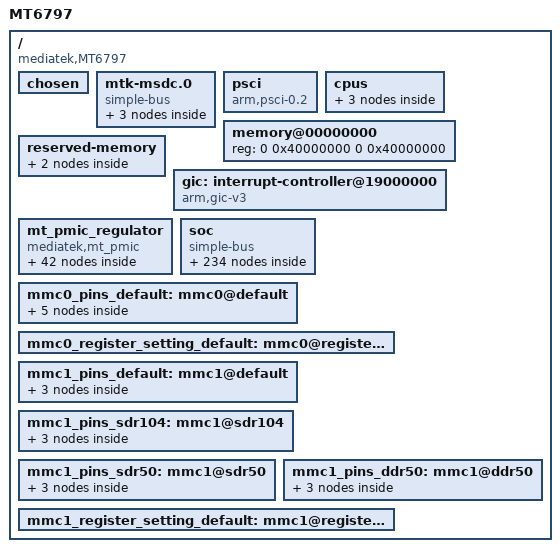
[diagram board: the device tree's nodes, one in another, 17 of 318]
/*
 * Mediatek's MT6797 SoC device tree source
 *
 * Copyright (c) 2013 MediaTek Co., Ltd.
 *              http://www.mediatek.com
 *
 */

#include <dt-bindings/interrupt-controller/arm-gic.h>
#include <dt-bindings/interrupt-controller/irq.h>
#include <dt-bindings/mmc/mt67xx-msdc.h>

/{
	model = "MT6797";
	compatible = "mediatek,MT6797";
	interrupt-parent = <&gic>;
	#address-cells = <2>;
	#size-cells = <2>;

	/* chosen */
	chosen {
		bootargs = "console=tty0 console=ttyMT0,921600n1 root=/dev/ram \
initrd=0x44000000,0x200000 loglevel=8 androidboot.selinux=permissive";
	};

	/* Do not put any bus before mtk-msdc, because it should be mtk-msdc.0 for partition device node usage */
	/* Kernel-3.18 can't transfer this node to mtk-msdc.0. So workaround here */
	mtk-msdc.0 {
		compatible = "simple-bus";
		#address-cells = <1>;
		#size-cells = <1>;
		ranges = <0 0 0 0xffffffff>;
		MSDC0@0x11230000 {
			compatible = "mediatek,MSDC0";
			reg = <0x11230000 0x10000>;
			interrupts = <GIC_SPI 79 IRQ_TYPE_LEVEL_LOW>;
			clk_src = /bits/ 8 <MSDC50_CLKSRC_400MHZ>;
			bus-width = <8>;
			max-frequency = <200000000>;
			cap-mmc-highspeed;
			msdc-sys-suspend;
			/* mmc-ddr-1_8v; */
			/* mmc-hs200-1_8v; */
			/* mmc-hs400-1_8v; */
			non-removable;
			pinctl = <&mmc0_pins_default>;
			register_setting = <&mmc0_register_setting_default>;
			host_function = /bits/ 8 <MSDC_EMMC>;
			bootable;
		};

		MSDC1@0x11240000 {
			compatible = "mediatek,MSDC1";
			reg = <0x11240000 0x10000>;
			interrupts = <GIC_SPI 80 IRQ_TYPE_LEVEL_LOW>;
			clk_src = /bits/ 8 <MSDC30_CLKSRC_200MHZ>;
			bus-width = <4>;
			max-frequency = <200000000>;
			msdc-sys-suspend;
			cap-sd-highspeed;
			sd-uhs-sdr12;
			sd-uhs-sdr25;
			sd-uhs-sdr50;
			sd-uhs-sdr104;
			sd-uhs-ddr50;
			pinctl = <&mmc1_pins_default>;
			pinctl_sdr104 = <&mmc1_pins_sdr104>;
			pinctl_sdr50 = <&mmc1_pins_sdr50>;
			pinctl_ddr50 = <&mmc1_pins_ddr50>;
			register_setting = <&mmc1_register_setting_default>;
			host_function = /bits/ 8 <MSDC_SD>;
			cd_level = /bits/ 8 <MSDC_CD_LOW>;
		};

		MSDC2@0x11250000 {
			compatible = "mediatek,MSDC2";
			reg = <0x11250000 0x10000>;
			interrupts = <GIC_SPI 81 IRQ_TYPE_LEVEL_LOW>;
		};

	};

	psci {
		compatible	= "arm,psci-0.2";
		method		= "smc";
		cpu_suspend	= <0x84000001>;
		cpu_off		= <0x84000002>;
		cpu_on		= <0x84000003>;
		affinity_info	= <0x84000004>;
	};

	cpus {
		#address-cells = <1>;
		#size-cells = <0>;

		cpu0: cpu@0 {
			device_type = "cpu";
			compatible = "arm,cortex-a53";
			reg = <0x000>;
			enable-method = "psci";
			cpu-release-addr = <0x0 0x40000200>;
			clock-frequency = <2000000000>;
		};

		cpu4: cpu@4 {
			device_type = "cpu";
			compatible = "arm,cortex-a53";
			reg = <0x100>;
			enable-method = "psci";
			cpu-release-addr = <0x0 0x40000200>;
			clock-frequency = <2000000000>;
		};

		cpu8: cpu@8 {
			device_type = "cpu";
			compatible = "arm,armv8";
			reg = <0x200>;
			enable-method = "psci";
			cpu-release-addr = <0x0 0x40000200>;
			clock-frequency = <2000000000>;
		};

	};

	memory@00000000 {
		device_type = "memory";
		reg = <0 0x40000000 0 0x40000000>;
		/*TODO: add memory node here*/
	};
	reserved-memory {
		#address-cells = <2>;
		#size-cells = <2>;
		ranges;

		ram_console-reserved-memory {
			compatible = "ram_console-reserve-memory";
			reg = <0 0x43F00000 0 0x10000>;
		};

		minirdump-reserved-memory {
			compatible = "minirdump-reserve-memory";
			reg = <0 0x43FF0000 0 0x10000>;
		};
	};
	gic: interrupt-controller@19000000 {
		compatible = "arm,gic-v3";
		#interrupt-cells = <3>;
		#address-cells = <2>;
		#size-cells = <2>;
		#redistributor-regions = <1>;
		interrupt-controller;
		reg = <0 0x19000000 0 0x40000>, // distributor
			<0 0x19200000 0 0x200000>, // redistributor
			<0 0x10220620 0 0x001000>; // INTPOL
		interrupts = <GIC_PPI 9 IRQ_TYPE_LEVEL_HIGH>;

	};
	mt_pmic_regulator {
		compatible = "mediatek,mt_pmic";
		/*reg = <0x01>*/
		buck_regulators {
			compatible = "mediatek,mt_pmic_buck_regulators";
			mt_pmic_vcore_buck_reg: buck_vcore {
				regulator-name = "vcore";
				regulator-min-microvolt = <600000>;
				regulator-max-microvolt = <1393750>;
				regulator-ramp-delay = <6250>;
				regulator-enable-ramp-delay = <180>;
			};
			mt_pmic_vgpu_buck_reg: buck_vgpu {
				regulator-name = "vgpu";
				regulator-min-microvolt = <600000>;
				regulator-max-microvolt = <1393750>;
				regulator-ramp-delay = <6250>;
				regulator-enable-ramp-delay = <180>;
				regulator-always-on;
				regulator-boot-on;
			};
			mt_pmic_vmodem_buck_reg: buck_vmodem {
				regulator-name = "vmodem";
				regulator-min-microvolt = <600000>;
				regulator-max-microvolt = <1393750>;
				regulator-ramp-delay = <6250>;
				regulator-enable-ramp-delay = <180>;
				regulator-always-on;
				regulator-boot-on;
			};
			mt_pmic_vmd1_buck_reg: buck_vmd1 {
				regulator-name = "vmd1";
				regulator-min-microvolt = <600000>;
				regulator-max-microvolt = <1393750>;
				regulator-ramp-delay = <6250>;
				regulator-enable-ramp-delay = <180>;
				regulator-always-on;
				regulator-boot-on;
			};
			mt_pmic_vsram_md_buck_reg: buck_vsram_md {
				regulator-name = "vsram_md";
				regulator-min-microvolt = <600000>;
				regulator-max-microvolt = <1393750>;
				regulator-ramp-delay = <6250>;
				regulator-enable-ramp-delay = <180>;
				regulator-always-on;
				regulator-boot-on;
			};
			mt_pmic_vs1_buck_reg: buck_vs1 {
				regulator-name = "vs1";
				regulator-min-microvolt = <600000>;
				regulator-max-microvolt = <1393750>;
				regulator-ramp-delay = <6250>;
				regulator-enable-ramp-delay = <180>;
				regulator-always-on;
				regulator-boot-on;
			};
			mt_pmic_vs2_buck_reg: buck_vs2 {
				regulator-name = "vs2";
				regulator-min-microvolt = <600000>;
				regulator-max-microvolt = <1393750>;
				regulator-ramp-delay = <6250>;
				regulator-enable-ramp-delay = <180>;
				regulator-always-on;
				regulator-boot-on;
			};
			mt_pmic_vpa_buck_reg: buck_vpa {
				regulator-name = "vpa";
				regulator-min-microvolt = <600000>;
				regulator-max-microvolt = <1393750>;
				regulator-ramp-delay = <6250>;
				regulator-enable-ramp-delay = <180>;
				regulator-always-on;
				regulator-boot-on;
			};
			mt_pmic_vsram_proc_buck_reg: buck_vsram_proc {
				regulator-name = "vsram_proc";
				regulator-min-microvolt = <600000>;
				regulator-max-microvolt = <1393750>;
				regulator-ramp-delay = <6250>;
				regulator-enable-ramp-delay = <180>;
				regulator-always-on;
				regulator-boot-on;
			};
		};	/* End of buck_regulators */
		ldo_regulators {
			compatible = "mediatek,mt_pmic_ldo_regulators";
			mt_pmic_va18_ldo_reg: ldo_va18 {
				regulator-name = "va18";
				regulator-min-microvolt = <1800000>;
				regulator-max-microvolt = <1800000>;
				regulator-enable-ramp-delay = <264>;
				regulator-boot-on;
			};
			mt_pmic_vtcxo24_ldo_reg: ldo_vtcxo24 {
				regulator-name = "vtcxo24";
				regulator-min-microvolt = <1800000>;
				regulator-max-microvolt = <2800000>;
				regulator-enable-ramp-delay = <110>;
				regulator-boot-on;
			};
			mt_pmic_vtcxo28_ldo_reg: ldo_vtcxo28 {
				regulator-name = "vtcxo28";
				regulator-min-microvolt = <1800000>;
				regulator-max-microvolt = <2800000>;
				regulator-enable-ramp-delay = <110>;
			};
			mt_pmic_vcn28_ldo_reg: ldo_vcn28 {
				regulator-name = "vcn28";
				regulator-min-microvolt = <1800000>;
				regulator-max-microvolt = <2800000>;
				regulator-enable-ramp-delay = <264>;
			};
			mt_pmic_vcama_ldo_reg: ldo_vcama {
				regulator-name = "vcama";
				regulator-min-microvolt = <1500000>;
				regulator-max-microvolt = <2800000>;
				regulator-enable-ramp-delay = <264>;
			};
			mt_pmic_vusb33_ldo_reg: ldo_vusb33 {
				regulator-name = "vusb33";
				regulator-min-microvolt = <3300000>;
				regulator-max-microvolt = <3300000>;
				regulator-enable-ramp-delay = <264>;
				regulator-boot-on;
			};
			mt_pmic_vsim1_ldo_reg: ldo_vsim1 {
				regulator-name = "vsim1";
				regulator-min-microvolt = <1700000>;
				regulator-max-microvolt = <3100000>;
				regulator-enable-ramp-delay = <264>;
			};
			mt_pmic_vsim2_ldo_reg: ldo_vsim2 {
				regulator-name = "vsim2";
				regulator-min-microvolt = <1700000>;
				regulator-max-microvolt = <3100000>;
				regulator-enable-ramp-delay = <264>;
			};
			mt_pmic_vemc_ldo_reg: ldo_vemc {
				regulator-name = "vemc_3v3";
				regulator-min-microvolt = <3000000>;
				regulator-max-microvolt = <3300000>;
				regulator-enable-ramp-delay = <44>;
				regulator-boot-on;
			};
			mt_pmic_vmch_ldo_reg: ldo_vmch {
				regulator-name = "vmch";
				regulator-min-microvolt = <3000000>;
				regulator-max-microvolt = <3300000>;
				regulator-enable-ramp-delay = <44>;
				regulator-boot-on;
			};
			mt_pmic_vio28_ldo_reg: ldo_vio28 {
				regulator-name = "vio28";
				regulator-min-microvolt = <2800000>;
				regulator-max-microvolt = <2800000>;
				regulator-enable-ramp-delay = <264>;
				regulator-boot-on;
			};
			mt_pmic_vibr_ldo_reg: ldo_vibr {
				regulator-name = "vibr";
				regulator-min-microvolt = <1200000>;
				regulator-max-microvolt = <3300000>;
				regulator-enable-ramp-delay = <44>;
			};
			mt_pmic_vcamd_ldo_reg: ldo_vcamd {
				regulator-name = "vcamd";
				regulator-min-microvolt = <900000>;
				regulator-max-microvolt = <1210000>;
				regulator-enable-ramp-delay = <264>;
			};
			mt_pmic_vrf18_ldo_reg: ldo_vrf18 {
				regulator-name = "vrf18";
				regulator-min-microvolt = <1000000>;
				regulator-max-microvolt = <1810000>;
				regulator-enable-ramp-delay = <220>;
			};
			mt_pmic_vio18_ldo_reg: ldo_vio18 {
				regulator-name = "vio18";
				regulator-min-microvolt = <1800000>;
				regulator-max-microvolt = <1800000>;
				regulator-enable-ramp-delay = <264>;
				regulator-boot-on;
			};
			mt_pmic_vcn18_ldo_reg: ldo_vcn18 {
				regulator-name = "vcn18";
				regulator-min-microvolt = <1800000>;
				regulator-max-microvolt = <1800000>;
				regulator-enable-ramp-delay = <44>;
			};
			mt_pmic_vcamio_ldo_reg: ldo_vcamio {
				regulator-name = "vcamio";
				regulator-min-microvolt = <1200000>;
				regulator-max-microvolt = <1800000>;
				regulator-enable-ramp-delay = <220>;
			};
			mt_pmic_vsram_proc_ldo_reg: ldo_vsram_proc {
				regulator-name = "vsram_proc";
				regulator-min-microvolt = <600000>;
				regulator-max-microvolt = <1393750>;
				regulator-enable-ramp-delay = <220>;
				regulator-boot-on;
			};
			mt_pmic_vxo22_ldo_reg: ldo_vxo22 {
				regulator-name = "vxo22";
				regulator-min-microvolt = <1800000>;
				regulator-max-microvolt = <2800000>;
				regulator-enable-ramp-delay = <110>;
				regulator-boot-on;
			};
			mt_pmic_vrf12_ldo_reg: ldo_vrf12 {
				regulator-name = "vrf12";
				regulator-min-microvolt = <900000>;
				regulator-max-microvolt = <1200000>;
				regulator-enable-ramp-delay = <220>;
			};
			mt_pmic_va10_ldo_reg: ldo_va10 {
				regulator-name = "va10";
				regulator-min-microvolt = <900000>;
				regulator-max-microvolt = <1800000>;
				regulator-enable-ramp-delay = <264>;
				regulator-boot-on;
			};
			mt_pmic_vdram_ldo_reg: ldo_vdram {
				regulator-name = "vdram";
				regulator-min-microvolt = <900000>;
				regulator-max-microvolt = <1210000>;
				regulator-enable-ramp-delay = <264>;
				regulator-boot-on;
			};
			mt_pmic_vmipi_ldo_reg: ldo_vmipi {
				regulator-name = "vmipi";
				regulator-min-microvolt = <900000>;
				regulator-max-microvolt = <1800000>;
				regulator-enable-ramp-delay = <264>;
			};
			mt_pmic_vgp3_ldo_reg: ldo_vgp3 {
				regulator-name = "vgp3";
				regulator-min-microvolt = <1000000>;
				regulator-max-microvolt = <1810000>;
				regulator-enable-ramp-delay = <264>;
			};
			mt_pmic_vbif28_ldo_reg: ldo_vbif28 {
				regulator-name = "vbif28";
				regulator-min-microvolt = <2800000>;
				regulator-max-microvolt = <2800000>;
				regulator-enable-ramp-delay = <264>;
			};
			mt_pmic_vefuse_ldo_reg: ldo_vefuse {
				regulator-name = "vefuse";
				regulator-min-microvolt = <1200000>;
				regulator-max-microvolt = <2200000>;
				regulator-enable-ramp-delay = <264>;
			};
			mt_pmic_vcn33_bt_ldo_reg: ldo_vcn33_bt {
				regulator-name = "vcn33_bt";
				regulator-min-microvolt = <3300000>;
				regulator-max-microvolt = <3600000>;
				regulator-enable-ramp-delay = <264>;
			};
			mt_pmic_vcn33_wifi_ldo_reg: ldo_vcn33_wifi {
				regulator-name = "vcn33_wifi";
				regulator-min-microvolt = <3300000>;
				regulator-max-microvolt = <3600000>;
				regulator-enable-ramp-delay = <264>;
			};
			mt_pmic_vldo28_ldo_reg: ldo_vldo28 {
				regulator-name = "vldo28";
				regulator-min-microvolt = <2800000>;
				regulator-max-microvolt = <2800000>;
				regulator-enable-ramp-delay = <264>;
			};
			mt_pmic_vmc_ldo_reg: ldo_vmc {
				regulator-name = "vmc";
				regulator-min-microvolt = <1200000>;
				regulator-max-microvolt = <3300000>;
				regulator-enable-ramp-delay = <44>;
				regulator-boot-on;
			};
		};/* End of ldo_regulators */
		regulators_supply {
			compatible = "mediatek,mt_pmic_regulator_supply";
			va18-supply = <&mt_pmic_va18_ldo_reg>;
			vtcxo24-supply = <&mt_pmic_vtcxo24_ldo_reg>;
			vtcxo28-supply = <&mt_pmic_vtcxo28_ldo_reg>;
			vsim1-supply = <&mt_pmic_vsim1_ldo_reg>;
			vsim2-supply = <&mt_pmic_vsim2_ldo_reg>;
			vemc-supply = <&mt_pmic_vemc_ldo_reg>;
			vmch-supply = <&mt_pmic_vmch_ldo_reg>;
			vmc-supply = <&mt_pmic_vmc_ldo_reg>;
			vio28-supply = <&mt_pmic_vio28_ldo_reg>;
			vibr-supply = <&mt_pmic_vibr_ldo_reg>;
			vrf18-supply = <&mt_pmic_vrf18_ldo_reg>;
			vio18-supply = <&mt_pmic_vio18_ldo_reg>;
			vsram_proc-supply = <&mt_pmic_vsram_proc_ldo_reg>;
			vxo22-supply = <&mt_pmic_vxo22_ldo_reg>;
			vrf12-supply = <&mt_pmic_vrf12_ldo_reg>;
			vdram-supply = <&mt_pmic_vdram_ldo_reg>;
			vmipi-supply = <&mt_pmic_vmipi_ldo_reg>;
			vbif28-supply = <&mt_pmic_vbif28_ldo_reg>;
			vefuse-supply = <&mt_pmic_vefuse_ldo_reg>;
			vcn18-supply = <&mt_pmic_vcn18_ldo_reg>;
			vcn28-supply = <&mt_pmic_vcn28_ldo_reg>;
			vcn33_bt-supply = <&mt_pmic_vcn33_bt_ldo_reg>;
			vcn33_wifi-supply = <&mt_pmic_vcn33_wifi_ldo_reg>;
		};/* End of regulators_supply */
	};/* End of mt_pmic_regulator */
	soc {
		compatible = "simple-bus";
		#address-cells = <1>;
		#size-cells = <1>;
		ranges = <0 0 0 0xffffffff>;

		chipid@08000000 {
			compatible = "mediatek,chipid";
			reg = <0x08000000 0x0004>,
					<0x08000004 0x0004>,
					<0x08000008 0x0004>,
					<0x0800000C 0x0004>;
		};

		topckgen@10000000 {
			compatible = "mediatek,topckgen";
			reg = <0x10000000 0x1000>;
		};

		infracfg_ao@10001000 {
			compatible = "mediatek,infracfg_ao";
			reg = <0x10001000 0x1000>;
		};

		iocfg_l@10002000 {
			compatible = "mediatek,iocfg_l";
			reg = <0x10002000 0x400>;
		};

		iocfg_b@10002400 {
			compatible = "mediatek,iocfg_b";
			reg = <0x10002400 0x400>;
		};

		iocfg_r@10002800 {
			compatible = "mediatek,iocfg_r";
			reg = <0x10002800 0x400>;
		};

		iocfg_t@10002c00 {
			compatible = "mediatek,iocfg_t";
			reg = <0x10002c00 0x400>;
		};

		pericfg@10003000 {
			compatible = "mediatek,pericfg";
			reg = <0x10003000 0x1000>;
		};

		dramc_conf@10004000 {
			compatible = "mediatek,dramc_conf";
			reg = <0x10004000 0x1000>;
		};

		gpio@10005000 {
			compatible = "mediatek,gpio";
			reg = <0x10005000 0x1000>;
		};

		sleep@10006000 {
			compatible = "mediatek,sleep";
			reg = <0x10006000 0x1000>;
			interrupts = <GIC_SPI 180 IRQ_TYPE_LEVEL_LOW>;
		};

		toprgu: toprgu@10007000 {
			compatible = "mediatek,mt6797-toprgu";
			reg = <0x10007000 0x1000>;
			interrupts = <GIC_SPI 137 IRQ_TYPE_EDGE_FALLING>;
		};

		cpuxgpt: cpuxgpt@10220000 {
			compatible = "mediatek,mt6797-cpuxgpt";
			reg = <0x10220000 0x1000>;
			interrupts = <GIC_SPI 64 IRQ_TYPE_LEVEL_HIGH>,
				<GIC_SPI 65 IRQ_TYPE_LEVEL_HIGH>,
				<GIC_SPI 66 IRQ_TYPE_LEVEL_HIGH>,
				<GIC_SPI 67 IRQ_TYPE_LEVEL_HIGH>,
				<GIC_SPI 68 IRQ_TYPE_LEVEL_HIGH>,
				<GIC_SPI 69 IRQ_TYPE_LEVEL_HIGH>,
				<GIC_SPI 70 IRQ_TYPE_LEVEL_HIGH>,
				<GIC_SPI 71 IRQ_TYPE_LEVEL_HIGH>,
				<GIC_SPI 322 IRQ_TYPE_LEVEL_HIGH>,
				<GIC_SPI 323 IRQ_TYPE_LEVEL_HIGH>;
		};

		apxgpt: apxgpt@10008000 {
			compatible = "mediatek,mt6797-apxgpt";
			reg = <0x10008000 0x1000>;
			interrupts = <GIC_SPI 169 IRQ_TYPE_LEVEL_LOW>;
			clock-frequency = <13000000>;
		};

		timer {
			compatible = "arm,armv8-timer";
			interrupts = <GIC_PPI 13 IRQ_TYPE_LEVEL_LOW>, /*Secure Physical Timer Event*/
				<GIC_PPI 14 IRQ_TYPE_LEVEL_LOW>, /*Non-Secure Physical Timer Event*/
				<GIC_PPI 11 IRQ_TYPE_LEVEL_LOW>, /*Virtual Timer Event*/
				<GIC_PPI 10 IRQ_TYPE_LEVEL_LOW>; /*Hypervisor Timer Event*/
				clock-frequency = <13000000>;
		};

		rsvd@10009000 {
			compatible = "mediatek,rsvd";
			reg = <0x10009000 0x1000>;
		};

		sej@1000a000 {
			compatible = "mediatek,sej";
			reg = <0x1000a000 0x1000>;
			interrupts = <GIC_SPI 196 IRQ_TYPE_LEVEL_LOW>;
		};

		eintc: eintc@1000b000 {
			compatible = "mediatek,mt-eic";
			reg = <0x1000b000 0x1000>;
			interrupts = <GIC_SPI 170 IRQ_TYPE_LEVEL_HIGH>;

			#interrupt-cells = <2>;
			interrupt-controller;

			max_eint_num = <192>;
			mapping_table_entry = <0>;
		};

		apmixed@1000c000 {
			compatible = "mediatek,apmixed";
			reg = <0x1000c000 0x1000>;
		};

		fhctl@1000cf00 {
			compatible = "mediatek,fhctl";
			reg = <0x1000cf00 0x100>;
		};

		pwrap@1000d000 {
			compatible = "mediatek,pwrap";
			reg = <0x1000d000 0x1000>;
			interrupts = <GIC_SPI 178 IRQ_TYPE_LEVEL_HIGH>;
		};

		devapc_ao@1000e000 {
			compatible = "mediatek,devapc_ao";
			reg = <0x1000e000 0x1000>;
		};

		ddrphy@1000f000 {
			compatible = "mediatek,ddrphy";
			reg = <0x1000f000 0x1000>;
		};

		kp@10010000 {
			compatible = "mediatek,kp";
			reg = <0x10010000 0x1000>;
			interrupts = <GIC_SPI 179 IRQ_TYPE_EDGE_FALLING>;
		};

		topmisc@10011000 {
			compatible = "mediatek,topmisc";
			reg = <0x10011000 0x1000>;
		};

		ddrphy_b@10012000 {
			compatible = "mediatek,ddrphy_b";
			reg = <0x10012000 0x1000>;
		};

		dramc_conf_b@10013000 {
			compatible = "mediatek,dramc_conf_b";
			reg = <0x10013000 0x1000>;
		};

		cldma_ao_ap@10014000 {
			compatible = "mediatek,cldma_ao_ap";
			reg = <0x10014000 0x1000>;
		};

		cldma_ao_md@10015000 {
			compatible = "mediatek,cldma_ao_md";
			reg = <0x10015000 0x1000>;
		};

		aes_top0@10016000 {
			compatible = "mediatek,aes_top0";
			reg = <0x10016000 0x1000>;
		};

		aes_top1@10017000 {
			compatible = "mediatek,aes_top1";
			reg = <0x10017000 0x1000>;
		};

		ddrphy_c@10018000 {
			compatible = "mediatek,ddrphy_c";
			reg = <0x10018000 0x1000>;
		};

		ddrphy_d@10019000 {
			compatible = "mediatek,ddrphy_d";
			reg = <0x10019000 0x1000>;
		};

		mcumixed@1001a000 {
			compatible = "mediatek,mcumixed";
			reg = <0x1001a000 0x1000>;
		};

		c2kmisc@1001b000 {
			compatible = "mediatek,c2kmisc";
			reg = <0x1001b000 0x1000>;
		};

		modem_temp@1001c000 {
			compatible = "mediatek,modem_temp";
			reg = <0x1001c000 0x1000>;
		};


		scp: scp@10020000 {
			compatible = "mediatek,scp";
			status = "disabled";
			reg = <0 0x10020000 0 0x80000>, // sram
			<0 0x100a0000 0 0x1000>,  // cfgreg
			<0 0x100a4000 0 0x1000>;	// clkctrl
			interrupts = <GIC_SPI 199 IRQ_TYPE_LEVEL_HIGH>;
		};

		emi_mpu@10200000 {
			compatible = "mediatek,emi_mpu";
			reg = <0x10200000 0x1000>;
		};

		infracfg@10201000 {
			compatible = "mediatek,infracfg";
			reg = <0x10201000 0x1000>;
		};

		sramrom@10202000 {
			compatible = "mediatek,sramrom";
			reg = <0x10202000 0x1000>;
		};

		emi@10203000 {
			compatible = "mediatek,emi";
			reg = <0x10203000 0x1000>;
			interrupts = <GIC_SPI 143 IRQ_TYPE_LEVEL_LOW>;
		};

		sys_cirq@10204000 {
			compatible = "mediatek,sys_cirq";
			reg = <0x10204000 0x1000>;
			interrupts = <GIC_SPI 291 IRQ_TYPE_EDGE_FALLING>;
		};

		m4u@10205000 {
			cell-index = <0>;
			compatible = "mediatek,m4u";
			reg = <0x10205000 0x1000>;
			interrupts = <GIC_SPI 156 IRQ_TYPE_LEVEL_LOW>;
		};

		efusec@10206000 {
			compatible = "mediatek,efusec";
			reg = <0x10206000 0x1000>;
		};

		devapc@10207000 {
			compatible = "mediatek,devapc";
			reg = <0x10207000 0x1000>;
			interrupts = <GIC_SPI 141 IRQ_TYPE_LEVEL_LOW>;
		};

		bus_dbg@10208000 {
			compatible = "mediatek,bus_dbg";
			reg = <0x10208000 0x1000>;
			interrupts = <GIC_SPI 140 IRQ_TYPE_LEVEL_LOW>;
		};

		ap_ccif0@10209000 {
			compatible = "mediatek,ap_ccif0";
			reg = <0x10209000 0x1000>;
			interrupts = <GIC_SPI 147 IRQ_TYPE_LEVEL_LOW>;
		};

		md_ccif0@1020a000 {
			compatible = "mediatek,md_ccif0";
			reg = <0x1020a000 0x1000>;
		};

		ap_ccif1@1020b000 {
			compatible = "mediatek,ap_ccif1";
			reg = <0x1020b000 0x1000>;
			interrupts = <GIC_SPI 149 IRQ_TYPE_LEVEL_LOW>;
		};

		ap_ccif1@1020c000 {
			compatible = "mediatek,ap_ccif1";
			reg = <0x1020c000 0x1000>;
		};

		infra_mbist@1020d000 {
			compatible = "mediatek,infra_mbist";
			reg = <0x1020d000 0x1000>;
		};

		dramc_nao@1020e000 {
			compatible = "mediatek,dramc_nao";
			reg = <0x1020e000 0x1000>;
			interrupts = <GIC_SPI 158 IRQ_TYPE_EDGE_FALLING>;
		};

		trng@1020f000 {
			compatible = "mediatek,trng";
			reg = <0x1020f000 0x1000>;
			interrupts = <GIC_SPI 148 IRQ_TYPE_LEVEL_LOW>;
		};

		gcpu@10210000 {
			compatible = "mediatek,gcpu";
			reg = <0x10210000 0x1000>;
			interrupts = <GIC_SPI 159 IRQ_TYPE_LEVEL_LOW>;
		};

		md2md_md1_ccif0@10211000 {
			compatible = "mediatek,md2md_md1_ccif0";
			reg = <0x10211000 0x1000>;
		};

		gce@10212000 {
			compatible = "mediatek,gce";
			reg = <0x10212000 0x1000>;
			interrupts = <GIC_SPI 152 IRQ_TYPE_LEVEL_LOW>,
				<GIC_SPI 153 IRQ_TYPE_LEVEL_LOW>;
			mdp_rdma0_sof = <0>;
			mdp_rdma1_sof = <1>;
			mdp_rsz0_sof = <2>;
			mdp_rsz1_sof = <3>;
			mdp_rsz2_sof = <4>;
			mdp_tdshp_sof = <5>;
			mdp_color_sof = <6>;
			mdp_wdma_sof = <7>;
			mdp_wrot0_sof = <8>;
			mdp_wrot1_sof = <9>;
			disp_ovl0_sof = <10>;
			disp_ovl1_sof = <11>;
			disp_2l_ovl0_sof = <12>;
			disp_2l_ovl1_sof = <13>;
			disp_rdma0_sof = <14>;
			disp_rdma1_sof = <15>;
			disp_wdma0_sof = <16>;
			disp_wdma1_sof = <17>;
			disp_color_sof = <18>;
			disp_ccorr_sof = <19>;
			disp_aal_sof = <20>;
			disp_gamma_sof = <21>;
			disp_od_sof = <22>;
			disp_dither_sof = <23>;
			disp_ufoe_sof = <24>;
			disp_dsc_sof = <25>;
			disp_pwm0_sof = <26>;
			mdp_rdma0_frame_done = <27>;
			mdp_rdma1_frame_done = <28>;
			mdp_rsz0_frame_done = <29>;
			mdp_rsz1_frame_done = <30>;
			mdp_rsz2_frame_done = <31>;
			mdp_tdshp_frame_done = <32>;
			mdp_color_frame_done = <33>;
			mdp_wdma_frame_done = <34>;
			mdp_wrot0_write_frame_done = <35>;
			mdp_wrot0_read_frame_done = <36>;
			mdp_wrot1_write_frame_done = <37>;
			mdp_wrot1_read_frame_done = <38>;
			disp_ovl0_frame_done = <39>;
			disp_ovl1_frame_done = <40>;
			disp_2l_ovl0_frame_done = <41>;
			disp_2l_ovl1_frame_done = <42>;
			disp_rdma0_frame_done = <43>;
			disp_rdma1_frame_done = <44>;
			disp_wdma0_frame_done = <45>;
			disp_wdma1_frame_done = <46>;
			disp_color_frame_done = <47>;
			disp_ccorr_frame_done = <48>;
			disp_aal_frame_done = <49>;
			disp_gamma_frame_done = <50>;
			disp_od_frame_done = <51>;
			disp_dither_frame_done = <52>;
			disp_ufoe_frame_done = <53>;
			disp_dsc_frame_done = <54>;
			disp_dsi0_frame_done = <55>;
			disp_dsi1_frame_done = <56>;
			disp_dpi0_frame_done = <57>;
			stream_done_0 = <58>;
			stream_done_1 = <59>;
			stream_done_2 = <60>;
			stream_done_3 = <61>;
			stream_done_4 = <62>;
			stream_done_5 = <63>;
			stream_done_6 = <64>;
			stream_done_7 = <65>;
			stream_done_8 = <66>;
			stream_done_9 = <67>;
			buf_underrun_event_0 = <68>;
			buf_underrun_event_1 = <69>;
			dsi0_te_event = <70>;
			dsi1_te_event = <71>;
			dip_cq_thread0_frame_done = <129>;
			dip_cq_thread1_frame_done = <130>;
			dip_cq_thread2_frame_done = <131>;
			dip_cq_thread3_frame_done = <132>;
			dip_cq_thread4_frame_done = <133>;
			dip_cq_thread5_frame_done = <134>;
			dip_cq_thread6_frame_done = <135>;
			dip_cq_thread7_frame_done = <136>;
			dip_cq_thread8_frame_done = <137>;
			dip_cq_thread9_frame_done = <138>;
			dip_cq_thread10_frame_done = <139>;
			dip_cq_thread11_frame_done = <140>;
			dip_cq_thread12_frame_done = <141>;
			dip_cq_thread13_frame_done = <142>;
			dip_cq_thread14_frame_done = <143>;
			dpe_frame_done = <144>;
			wmf_frame_done = <145>;
			venc_done = <257>;
			jpgdec_done = <258>;
			jpgenc_done = <259>;
			venc_mb_done = <260>;
			venc_128byte_cnt_done = <261>;
			isp_frame_done_a = <385>;
			isp_frame_done_b = <386>;
			camsv_0_pass1_done = <387>;
			camsv_1_pass1_done = <388>;
			camsv_2_pass1_done = <389>;
			seninf_0_fifo_full = <390>;
			seninf_1_fifo_full = <391>;
			seninf_2_fifo_full = <392>;
			seninf_3_fifo_full = <393>;
			seninf_4_fifo_full = <394>;
			seninf_5_fifo_full = <395>;
			seninf_6_fifo_full = <396>;
			seninf_7_fifo_full = <397>;
		};

		md2md_md2_ccif0@10213000 {
			compatible = "mediatek,md2md_md2_ccif0";
			reg = <0x10213000 0x1000>;
		};

		mipi_tx0@10215000 {
			compatible = "mediatek,mipi_tx0";
			reg = <0x10215000 0x1000>;
		};

		dramc_b_nao@10216000 {
			compatible = "mediatek,dramc_b_nao";
			reg = <0x10216000 0x1000>;
		};

		mipi_rx_ana_csi0@10217000 {
			compatible = "mediatek,mipi_rx_ana_csi0";
			reg = <0x10217000 0x1000>;
		};

		mipi_rx_ana_csi1@10218000 {
			compatible = "mediatek,mipi_rx_ana_csi1";
			reg = <0x10218000 0x1000>;
		};

		ap_cldma@10219000 {
			compatible = "mediatek,ap_cldma";
			reg = <0x10219000 0x1000>;
		};

		md_cldma@1021a000 {
			compatible = "mediatek,md_cldma";
			reg = <0x1021a000 0x1000>;
		};

		mdhw_smi@1021c000 {
			compatible = "mediatek,mdhw_smi";
			reg = <0x1021c000 0x1000>;
		};

		gcpu_rsa@1021d000 {
			compatible = "mediatek,gcpu_rsa";
			reg = <0x1021d000 0x1000>;
		};

		mipi_tx1@1021e000 {
			compatible = "mediatek,mipi_tx1";
			reg = <0x1021e000 0x1000>;
		};

		vad@1021f000 {
			compatible = "mediatek,vad";
			reg = <0x1021f000 0x1000>;
		};

		mcucfg@10220000 {
			compatible = "mediatek,mcucfg";
			reg = <0x10220000 0x1000>;
		};

		gic@10240000 {
			compatible = "mediatek,gic";
			reg = <0x10240000 0x40000>;
		};

		dbgapb@10300000 {
			compatible = "mediatek,dbgapb";
			reg = <0x10300000 0xd00000>;
			interrupts = <GIC_SPI 139 IRQ_TYPE_LEVEL_LOW>;
		};

		gic1@19000000 {
			compatible = "mediatek,gic1";
			reg = <0x19000000 0x400000>;
		};

		ap_dma@11000000 {
			compatible = "mediatek,ap_dma";
			reg = <0x11000000 0x1000>;
			interrupts = <GIC_SPI 97 IRQ_TYPE_LEVEL_LOW>;
		};

		auxadc@11001000 {
			compatible = "mediatek,auxadc";
			reg = <0x11001000 0x1000>;
			interrupts = <GIC_SPI 74 0x2>;
		};

		apuart0: apuart0@11002000 {
			cell-index = <0>;
			compatible = "mediatek,mt6735-uart";
			reg = <0x11002000 0x1000>, /* UART base */
				  <0x11000600 0x1000>, /* DMA Tx base */
				  <0x11000680 0x80>; /* DMA Rx base */
			interrupts = <GIC_SPI 91 IRQ_TYPE_LEVEL_LOW>, /* UART IRQ */
						 <GIC_SPI 108 IRQ_TYPE_LEVEL_LOW>, /* DMA Tx IRQ */
						 <GIC_SPI 109 IRQ_TYPE_LEVEL_LOW>; /* DMA Rx IRQ */
		};

		apuart1: apuart1@11003000 {
			cell-index = <1>;
			compatible = "mediatek,mt6735-uart";
			reg = <0x11003000 0x1000>, /* UART base */
				  <0x11000700 0x80>, /* DMA Tx base */
				  <0x11000780 0x80>; /* DMA Rx base */
			interrupts = <GIC_SPI 92 IRQ_TYPE_LEVEL_LOW>, /* UART IRQ */
						 <GIC_SPI 110 IRQ_TYPE_LEVEL_LOW>, /* DMA Tx IRQ */
						 <GIC_SPI 111 IRQ_TYPE_LEVEL_LOW>; /* DMA Rx IRQ */
		};

		apuart2: apuart2@11004000 {
			cell-index = <2>;
			compatible = "mediatek,mt6735-uart";
			reg = <0x11004000 0x1000>, /* UART base */
				  <0x11000800 0x80>, /* DMA Tx base */
				  <0x11000880 0x80>; /* DMA Rx base */
			interrupts = <GIC_SPI 93 IRQ_TYPE_LEVEL_LOW>, /* UART IRQ */
						 <GIC_SPI 112 IRQ_TYPE_LEVEL_LOW>, /* DMA Tx IRQ */
						 <GIC_SPI 113 IRQ_TYPE_LEVEL_LOW>; /* DMA Rx IRQ */
		};

		apuart3: apuart3@11005000 {
			cell-index = <3>;
			compatible = "mediatek,mt6735-uart";
			reg = <0x11005000 0x1000>, /* UART base */
				  <0x11000900 0x80>, /* DMA Tx base */
				  <0x11000980 0x80>; /* DMA Rx base */
			interrupts = <GIC_SPI 94 IRQ_TYPE_LEVEL_LOW>, /* UART IRQ */
						 <GIC_SPI 114 IRQ_TYPE_LEVEL_LOW>, /* DMA Tx IRQ */
						 <GIC_SPI 115 IRQ_TYPE_LEVEL_LOW>; /* DMA Rx IRQ */
		};

		pwm@11006000 {
			compatible = "mediatek,pwm";
			reg = <0x11006000 0x1000>;
			interrupts = <GIC_SPI 77 IRQ_TYPE_LEVEL_LOW>;
		};

		i2c0@11007000 {
			compatible = "mediatek,i2c0";
			cell-index = <0>;
			reg = <0x11007000 0x1000>;
			interrupts = <GIC_SPI 84 IRQ_TYPE_LEVEL_LOW>;
		};

		i2c1@11008000 {
			compatible = "mediatek,i2c1";
			cell-index = <1>;
			reg = <0x11008000 0x1000>;
			interrupts = <GIC_SPI 85 IRQ_TYPE_LEVEL_LOW>;
		};

		i2c2@11009000 {
			compatible = "mediatek,i2c2";
			cell-index = <2>;
			reg = <0x11009000 0x1000>;
			interrupts = <GIC_SPI 86 IRQ_TYPE_LEVEL_LOW>;
		};

		i2c3@1100d000 {
			compatible = "mediatek,i2c3";
			cell-index = <3>;
			reg = <0x1100d000 0x1000>;
			interrupts = <GIC_SPI 87 IRQ_TYPE_LEVEL_LOW>;
		};

		i2c4@11011000 {
			compatible = "mediatek,i2c4";
			cell-index = <4>;
			reg = <0x11011000 0x1000>;
			interrupts = <GIC_SPI 90 IRQ_TYPE_LEVEL_LOW>;
		};

		i2c5@1101c000 {
			compatible = "mediatek,i2c5";
			cell-index = <5>;
			reg = <0x1101c000 0x1000>;
			interrupts = <GIC_SPI 83 IRQ_TYPE_LEVEL_LOW>;
		};

		i2c_appm@1100e000 {
			compatible = "mediatek,i2c_appm";
			cell-index = <6>;
			reg = <0x1100e000 0x1000>;
			interrupts = <GIC_SPI 88 IRQ_TYPE_LEVEL_LOW>;
		};

		i2c_gpupm@11010000 {
			compatible = "mediatek,i2c_gpupm";
			cell-index = <7>;
			reg = <0x11010000 0x1000>;
			interrupts = <GIC_SPI 89 IRQ_TYPE_LEVEL_LOW>;
		};

		i2c2_imm@11013000 {
			compatible = "mediatek,i2c2_imm";
			cell-index = <8>;
			reg = <0x11013000 0x1000>;
			interrupts = <GIC_SPI 95 IRQ_TYPE_LEVEL_LOW>;
		};

		i2c3_imm@11014000 {
			compatible = "mediatek,i2c3_imm";
			cell-index = <9>;
			reg = <0x11014000 0x1000>;
			interrupts = <GIC_SPI 96 IRQ_TYPE_LEVEL_LOW>;
		};

		i2c_dual@1100e000 {
			compatible = "mediatek,i2c_dual";
			cell-index = <10>;
			reg = <0x1100e000 0x1000>;
			interrupts = <GIC_SPI 128 IRQ_TYPE_LEVEL_LOW>;
		};

		spi1@1100a000 {
			compatible = "mediatek,spi1";
			reg = <0x1100a000 0x1000>;
			interrupts = <GIC_SPI 122 IRQ_TYPE_LEVEL_LOW>;
		};

		therm_ctrl@1100b000 {
			compatible = "mediatek,therm_ctrl";
			reg = <0x1100b000 0x1000>;
			interrupts = <GIC_SPI 78 IRQ_TYPE_LEVEL_LOW>;
		};

		btif@1100c000 {
			compatible = "mediatek,btif";
			reg = <0x1100c000 0x1000>;
			interrupts = <GIC_SPI 130 IRQ_TYPE_LEVEL_LOW>;
		};

		ap_dma_btif_tx@11000a00 {
			compatible = "mediatek,ap_dma_btif_tx";
			reg = <0x11000a00 0x80>;
			interrupts = <GIC_SPI 116 IRQ_TYPE_LEVEL_LOW>;
		};

		ap_dma_btif_rx@11000a80 {
			compatible = "mediatek,ap_dma_btif_rx";
			reg = <0x11000a80 0x80>;
			interrupts = <GIC_SPI 117 IRQ_TYPE_LEVEL_LOW>;
		};

		pwm_disp@1100f000 {
			compatible = "mediatek,pwm_disp";
			reg = <0x1100f000 0x1000>;
		};

		spi1@11012000 {
			compatible = "mediatek,spi1";
			reg = <0x11012000 0x1000>;
			interrupts = <GIC_SPI 131 IRQ_TYPE_LEVEL_LOW>;
		};

		dvfs_proc1@11015000 {
			compatible = "mediatek,dvfs_proc1";
			reg = <0x11015000 0x1000>;
			interrupts = <GIC_SPI 161 IRQ_TYPE_NONE>;
		};

		dvfs_proc2@11016000 {
			compatible = "mediatek,dvfs_proc2";
			reg = <0x11016000 0x1000>;
			interrupts = <GIC_SPI 165 IRQ_TYPE_NONE>;
		};

		spi2@11018000 {
			compatible = "mediatek,spi2";
			reg = <0x11018000 0x1000>;
			interrupts = <GIC_SPI 132 IRQ_TYPE_LEVEL_LOW>;
		};

		spi3@11019000 {
			compatible = "mediatek,spi3";
			reg = <0x11019000 0x1000>;
			interrupts = <GIC_SPI 133 IRQ_TYPE_LEVEL_LOW>;
		};

		spi4@1101a000 {
			compatible = "mediatek,spi4";
			reg = <0x1101a000 0x1000>;
			interrupts = <GIC_SPI 134 IRQ_TYPE_LEVEL_LOW>;
		};

		spi5@1101b000 {
			compatible = "mediatek,spi5";
			reg = <0x1101b000 0x1000>;
			interrupts = <GIC_SPI 135 IRQ_TYPE_LEVEL_LOW>;
		};

		irtx@1101d000 {
			compatible = "mediatek,irtx";
			reg = <0x1101d000 0x1000>;
			interrupts = <GIC_SPI 136 IRQ_TYPE_LEVEL_HIGH>;
		};

		anc_md32@11020000 {
			compatible = "mediatek,anc_md32";
			reg = <0x11020000 0x6000>;
		};

		usbphy0:usbphy@0 {
			 compatible = "usb-nop-xceiv";
		};

		audio@11220000 {
			compatible = "mediatek,audio";
			reg = <0x11220000 0x10000>;
			interrupts = <GIC_SPI 151 IRQ_TYPE_LEVEL_LOW>;
		};

		audgpio:mt_soc_dl1_pcm@11220000 {
			compatible = "mediatek,mt-soc-dl1-pcm";
			reg = <0x11220000 0x1000>;
			interrupts = <GIC_SPI 151 IRQ_TYPE_LEVEL_LOW>;
			/*clocks = <&audiosys audio_afe>,
				<&audiosys audio_i2s>,
				<&audiosys audio_dac>,
				<&audiosys audio_dac_predis>,
				<&audiosys audio_adc>,
				<&audiosys audio_22m>,
				<&audiosys audio_24m>,
				<&audiosys audio_apll_tuner>,
				<&audiosys audio_apll2_tuner>,
				<&audiosys audio_tml>,
				<&infrasys infra_audio>,
				<&topckgen top_mux_aud1>,
				<&topckgen top_mux_aud2>,
				<&topckgen top_ad_apll1_ck>,
				<&topckgen top_whpll_audio_ck>,
				<&topckgen top_mux_audintbus>,
				<&topckgen top_syspll1_d4>,
				<&apmixedsys apmixed_apll1>,
				<&apmixedsys apmixed_apll2>,
				<&clk26m>;
			clock-names = "aud_afe_clk",
				"aud_i2s_clk",
				"aud_dac_clk",
				"aud_dac_predis_clk",
				"aud_adc_clk",
				"aud_apll22m_clk",
				"aud_apll24m_clk",
				"aud_apll1_tuner_clk",
				"aud_apll2_tuner_clk",
				"aud_tml_clk",
				"aud_infra_clk",
				"aud_mux1_clk",
				"aud_mux2_clk",
				"top_ad_apll1_clk",
				"top_whpll_audio_clk",
				"top_mux_audio_int",
				"top_sys_pll1_d4",
				"apmixed_apll1_clk",
				"apmixed_apll2_clk",
				"top_clk26m_clk";*/
			audclk-gpio = <143 0>;
			audmiso-gpio = <144 0>;
			audmosi-gpio = <145 0>;
			vowclk-gpio = <148 0>;
			extspkamp-gpio = <117 0>;
			i2s1clk-gpio = <80 0>;
			i2s1dat-gpio = <78 0>;
			i2s1mclk-gpio = <9 0>;
			i2s1ws-gpio = <79 0>;
		};

		mt_soc_ul1_pcm@11220000 {
			compatible = "mediatek,mt_soc_pcm_capture";
		};

		mt_soc_voice_md1@11220000 {
			compatible = "mediatek,mt_soc_pcm_voice_md1";
		};

		mt_soc_hdmi_pcm@11220000 {
			compatible = "mediatek,mt_soc_pcm_hdmi";
		};

		mt_soc_uldlloopback_pcm@11220000 {
			compatible = "mediatek,mt_soc_pcm_uldlloopback";
		};

		mt_soc_i2s0_pcm@11220000 {
			compatible = "mediatek,mt_soc_pcm_dl1_i2s0";
		};

		mt_soc_mrgrx_pcm@11220000 {
			compatible = "mediatek,mt_soc_pcm_mrgrx";
		};

		mt_soc_mrgrx_awb_pcm@11220000 {
			compatible = "mediatek,mt_soc_pcm_mrgrx_awb";
		};

		mt_soc_fm_i2s_pcm@11220000 {
			compatible = "mediatek,mt_soc_pcm_fm_i2s";
		};

		mt_soc_fm_i2s_awb_pcm@11220000 {
			compatible = "mediatek,mt_soc_pcm_fm_i2s_awb";
		};

		mt_soc_i2s0dl1_pcm@11220000 {
			compatible = "mediatek,mt_soc_pcm_dl1_i2s0dl1";
		};

		mt_soc_dl1_awb_pcm@11220000 {
			compatible = "mediatek,mt_soc_pcm_dl1_awb";
		};

		mt_soc_voice_md1_bt@11220000 {
			compatible = "mediatek,mt_soc_pcm_voice_md1_bt";
		};

		mt_soc_voip_bt_out@11220000 {
			compatible = "mediatek,mt_soc_pcm_dl1_bt";
		};

		mt_soc_voip_bt_in@11220000 {
			compatible = "mediatek,mt_soc_pcm_bt_dai";
		};

		mt_soc_tdmrx_pcm@11220000 {
			compatible = "mediatek,mt_soc_tdm_capture";
		};

		mt_soc_fm_mrgtx_pcm@11220000 {
			compatible = "mediatek,mt_soc_pcm_fmtx";
		};

		mt_soc_ul2_pcm@11220000 {
			compatible = "mediatek,mt_soc_pcm_capture2";
		};

		mt_soc_i2s0_awb_pcm@11220000 {
			compatible = "mediatek,mt_soc_pcm_i2s0_awb";
		};

		mt_soc_voice_md2@11220000 {
			compatible = "mediatek,mt_soc_pcm_voice_md2";
		};

		mt_soc_routing_pcm@11220000 {
			compatible = "mediatek,mt_soc_pcm_routing";
			/*i2s1clk-gpio = <7 6>;
			i2s1dat-gpio = <5 6>;
			i2s1mclk-gpio = <9 6>;
			i2s1ws-gpio = <6 6>;*/
		};

		mt_soc_voice_md2_bt@11220000 {
			compatible = "mediatek,mt_soc_pcm_voice_md2_bt";
		};

		mt_soc_hp_impedance_pcm@11220000 {
			compatible = "mediatek,mt_soc_pcm_hp_impedance";
		};

		mt_soc_codec_name@11220000 {
			compatible = "mediatek,mt_soc_codec_63xx";
		};

		mt_soc_dummy_pcm@11220000 {
			compatible = "mediatek,mt_soc_pcm_dummy";
		};

		mt_soc_codec_dummy_name@11220000 {
			compatible = "mediatek,mt_soc_codec_dummy";
		};

		mt_soc_routing_dai_name@11220000 {
			compatible = "mediatek,mt_soc_dai_routing";
		};

		mt_soc_dai_name@11220000 {
			compatible = "mediatek,mt_soc_dai_stub";
		};

		mt_soc_offload_gdma@11220000 {
			compatible = "mediatek,mt_soc_pcm_offload_gdma";
		};

		usb3@11270000 {
			compatible = "mediatek,usb3";
			reg = <0x11270000 0x10000>, <0x11280000 0x10000>, <0x11290000 0x10000>;
			reg-names = "ssusb_base", "ssusb_sif", "ssusb_sif2";
			interrupts = <GIC_SPI 127 IRQ_TYPE_LEVEL_LOW>, <GIC_SPI 126 IRQ_TYPE_LEVEL_LOW>;
			interrupt-names = "musb-hdrc", "xhci";
		};

		usb3_sif@11280000 {
			compatible = "mediatek,usb3_sif";
			reg = <0x11280000 0x10000>;
		};

		usb3_sif2@11290000 {
			compatible = "mediatek,usb3_sif2";
			reg = <0x11290000 0x10000>;
		};

		smi_larb4@12002000 {
			compatible = "mediatek,smi_larb4";
			reg = <0x12002000 0x1000>;
			interrupts = <GIC_SPI 242 IRQ_TYPE_LEVEL_LOW>;
		};

		g3d_config@13000000 {
			compatible = "mediatek,g3d_config";
			reg = <0x13000000 0x1000>;
		};

		g3d_vad_config@13001000 {
			compatible = "mediatek,g3d_vad_config";
			reg = <0x13001000 0x1000>;
		};

		g3d_dfp_config@13020000 {
			compatible = "mediatek,g3d_dfp_config";
			reg = <0x13020000 0x1000>;
		};

		mali@13040000 {
			compatible = "mediatek,mali";
			reg = <0x13040000 0x40000>;
			interrupts = <GIC_SPI 262 IRQ_TYPE_LEVEL_LOW>;
		};

		mmsys_config@14000000 {
			compatible = "mediatek,mmsys_config";
			reg = <0x14000000 0x1000>;
			interrupts = <GIC_SPI 232 IRQ_TYPE_LEVEL_LOW>;
		};

		mdp_rdma0@14001000 {
			compatible = "mediatek,mdp_rdma0";
			reg = <0x14001000 0x1000>;
			interrupts = <GIC_SPI 203 IRQ_TYPE_LEVEL_LOW>;
		};

		mdp_rdma1@14002000 {
			compatible = "mediatek,mdp_rdma1";
			reg = <0x14002000 0x1000>;
			interrupts = <GIC_SPI 204 IRQ_TYPE_LEVEL_LOW>;
		};

		mdp_rsz0@14003000 {
			compatible = "mediatek,mdp_rsz0";
			reg = <0x14003000 0x1000>;
			interrupts = <GIC_SPI 205 IRQ_TYPE_LEVEL_LOW>;
		};

		mdp_rsz1@14004000 {
			compatible = "mediatek,mdp_rsz1";
			reg = <0x14004000 0x1000>;
			interrupts = <GIC_SPI 206 IRQ_TYPE_LEVEL_LOW>;
		};

		mdp_rsz2@14005000 {
			compatible = "mediatek,mdp_rsz2";
			reg = <0x14005000 0x1000>;
			interrupts = <GIC_SPI 207 IRQ_TYPE_LEVEL_LOW>;
		};

		mdp_wdma@14006000 {
			compatible = "mediatek,mdp_wdma";
			reg = <0x14006000 0x1000>;
			interrupts = <GIC_SPI 210 IRQ_TYPE_LEVEL_LOW>;
		};

		mdp_wrot0@14007000 {
			compatible = "mediatek,mdp_wrot0";
			reg = <0x14007000 0x1000>;
			interrupts = <GIC_SPI 211 IRQ_TYPE_LEVEL_LOW>;
		};

		mdp_wrot1@14008000 {
			compatible = "mediatek,mdp_wrot1";
			reg = <0x14008000 0x1000>;
			interrupts = <GIC_SPI 212 IRQ_TYPE_LEVEL_LOW>;
		};

		mdp_tdshp@14009000 {
			compatible = "mediatek,mdp_tdshp";
			reg = <0x14009000 0x1000>;
			interrupts = <GIC_SPI 208 IRQ_TYPE_LEVEL_LOW>;
		};

		mdp_color@1400a000 {
			compatible = "mediatek,mdp_color";
			reg = <0x1400a000 0x1000>;
			interrupts = <GIC_SPI 209 IRQ_TYPE_LEVEL_LOW>;
		};

		mtkfb@0 {
			compatible = "mediatek,mtkfb";
		};

		dispsys@14000000 {
			compatible = "mediatek,dispsys";
			reg = <0x14000000 0x1000>,  /*disp_sys		*/
			      <0x1400b000 0x1000>,  /*disp_ovl0		*/
			      <0x1400c000 0x1000>,  /*disp_ovl1		*/
			      <0x1400d000 0x1000>,  /*disp_ovl0_2l	*/
			      <0x1400e000 0x1000>,  /*disp_ovl1_2l	*/
			      <0x1400f000 0x1000>,  /*disp_rdma0	*/
			      <0x14010000 0x1000>,  /*disp_rdma1	*/
			      <0x14011000 0x1000>,  /*disp_wdma0	*/
			      <0x14013000 0x1000>,  /*disp_color	*/
			      <0x14014000 0x1000>,  /*disp_ccorr	*/
			      <0x14015000 0x1000>,  /*disp_aal		*/
			      <0x14016000 0x1000>,  /*disp_gamma	*/
			   /*   <0x14017000 0x1000>,  //disp_od		*/
			      <0x14018000 0x1000>,  /*disp_dither	*/
			   /*   <0x14019000 0x1000>,  //disp_dsi_ufoe	*/
			   /*   <0x1401a000 0x1000>,  //disp_dsi_dsc	*/
			   /*   <0x1401b000 0x1000>,  //disp_dsi_split	*/
			      <0x1401c000 0x1000>,  /*disp_dsi0		*/
			   /*   <0x1401d000 0x1000>,  //disp_dsi1		*/
			      <0x1401e000 0x1000>,  /*disp_dpi0		*/
			      <0x1100f000 0x1000>,  /*disp_pwm		*/
			      <0x1401f000 0x1000>,  /*disp_mm_mutex	*/
			      <0x14020000 0x1000>,  /*disp_smi_larb0	*/
			      <0x14021000 0x1000>,  /*disp_smi_larb5	*/
			      <0x14022000 0x1000>,  /*disp_smi_commom	*/
			      <0x14012000 0x1000>,  /*disp_wdma1	*/
				<0x0 0x1000>,
				/*mipitx0,real chip would use this:<0x14018000 0x1000>;*/
				/* not in everest coda */
			      <0x14024000 0x1000>;


			interrupts = <GIC_SPI 0 IRQ_TYPE_LEVEL_LOW>, /*disp_sys */
				<GIC_SPI 213 IRQ_TYPE_LEVEL_LOW>, /*disp_ovl0 */
				<GIC_SPI 214 IRQ_TYPE_LEVEL_LOW>, /*disp_ovl1 */
				<GIC_SPI 215 IRQ_TYPE_LEVEL_LOW>, /*disp_ovl0_2l */
				<GIC_SPI 216 IRQ_TYPE_LEVEL_LOW>, /*disp_ovl1_2l */
				<GIC_SPI 217 IRQ_TYPE_LEVEL_LOW>, /*disp_rdma0 */
				<GIC_SPI 218 IRQ_TYPE_LEVEL_LOW>, /*disp_rdma1 */
				<GIC_SPI 219 IRQ_TYPE_LEVEL_LOW>, /*disp_wdma0 */
				<GIC_SPI 221 IRQ_TYPE_LEVEL_LOW>, /*disp_color */
				<GIC_SPI 222 IRQ_TYPE_LEVEL_LOW>, /*disp_ccorr */
				<GIC_SPI 223 IRQ_TYPE_LEVEL_LOW>, /*disp_aal */
				<GIC_SPI 224 IRQ_TYPE_LEVEL_LOW>, /*disp_gamma */
			/*	<GIC_SPI 225 IRQ_TYPE_LEVEL_LOW>, //disp_od */
				<GIC_SPI 226 IRQ_TYPE_LEVEL_LOW>, /*disp_dither */
			/*	<GIC_SPI 227 IRQ_TYPE_LEVEL_LOW>, //disp_ufoe */
			/*	<GIC_SPI 228 IRQ_TYPE_LEVEL_LOW>, //disp_dsc */
				<GIC_SPI 229 IRQ_TYPE_LEVEL_LOW>, /*disp_dsi0 */
			/*	<GIC_SPI 230 IRQ_TYPE_LEVEL_LOW>, //disp_dsi1 */
				<GIC_SPI 231 IRQ_TYPE_LEVEL_LOW>, /*disp_dpi0 */
				<GIC_SPI 0 IRQ_TYPE_LEVEL_LOW>, /*disp_pwm */
				<GIC_SPI 202 IRQ_TYPE_LEVEL_LOW>, /*disp_mutex */
				<GIC_SPI 233 IRQ_TYPE_LEVEL_LOW>, /*disp_smi_larb0 */
				<GIC_SPI 234 IRQ_TYPE_LEVEL_LOW>, /*disp_smi_larb5 */
				<GIC_SPI 0 IRQ_TYPE_LEVEL_LOW>, /*disp_smi_commom*/ /* not in everest coda */
				<GIC_SPI 220 IRQ_TYPE_LEVEL_LOW>, /*disp_wdma1 */
				<GIC_SPI 0 IRQ_TYPE_LEVEL_LOW>; /*mipitx0*/ /* not in everest coda */
		};
		disp_ovl0@1400b000 {
			compatible = "mediatek,disp_ovl0";
			reg = <0x1400b000 0x1000>;
			interrupts = <GIC_SPI 213 IRQ_TYPE_LEVEL_LOW>;
		};

		disp_ovl1@1400c000 {
			compatible = "mediatek,disp_ovl1";
			reg = <0x1400c000 0x1000>;
			interrupts = <GIC_SPI 214 IRQ_TYPE_LEVEL_LOW>;
		};

		disp_ovl0_2l@1400d000 {
			compatible = "mediatek,disp_ovl0_2l";
			reg = <0x1400d000 0x1000>;
			interrupts = <GIC_SPI 215 IRQ_TYPE_LEVEL_LOW>;
		};

		disp_ovl1_2l@1400e000 {
			compatible = "mediatek,disp_ovl1_2l";
			reg = <0x1400e000 0x1000>;
			interrupts = <GIC_SPI 216 IRQ_TYPE_LEVEL_LOW>;
		};

		disp_rdma0@1400f000 {
			compatible = "mediatek,disp_rdma0";
			reg = <0x1400f000 0x1000>;
			interrupts = <GIC_SPI 217 IRQ_TYPE_LEVEL_LOW>;
		};

		disp_rdma1@14010000 {
			compatible = "mediatek,disp_rdma1";
			reg = <0x14010000 0x1000>;
			interrupts = <GIC_SPI 218 IRQ_TYPE_LEVEL_LOW>;
		};

		disp_wdma0@14011000 {
			compatible = "mediatek,disp_wdma0";
			reg = <0x14011000 0x1000>;
			interrupts = <GIC_SPI 219 IRQ_TYPE_LEVEL_LOW>;
		};

		disp_wdma1@14012000 {
			compatible = "mediatek,disp_wdma1";
			reg = <0x14012000 0x1000>;
			interrupts = <GIC_SPI 220 IRQ_TYPE_LEVEL_LOW>;
		};

		disp_color@14013000 {
			compatible = "mediatek,disp_color";
			reg = <0x14013000 0x1000>;
			interrupts = <GIC_SPI 221 IRQ_TYPE_LEVEL_LOW>;
		};

		disp_ccorr@14014000 {
			compatible = "mediatek,disp_ccorr";
			reg = <0x14014000 0x1000>;
			interrupts = <GIC_SPI 222 IRQ_TYPE_LEVEL_LOW>;
		};

		disp_aal@14015000 {
			compatible = "mediatek,disp_aal";
			reg = <0x14015000 0x1000>;
			interrupts = <GIC_SPI 223 IRQ_TYPE_LEVEL_LOW>;
		};

		disp_gamma@14016000 {
			compatible = "mediatek,disp_gamma";
			reg = <0x14016000 0x1000>;
			interrupts = <GIC_SPI 224 IRQ_TYPE_LEVEL_LOW>;
		};

		disp_od@14017000 {
			compatible = "mediatek,disp_od";
			reg = <0x14017000 0x1000>;
			interrupts = <GIC_SPI 225 IRQ_TYPE_LEVEL_LOW>;
		};

		disp_dither@14018000 {
			compatible = "mediatek,disp_dither";
			reg = <0x14018000 0x1000>;
			interrupts = <GIC_SPI 226 IRQ_TYPE_LEVEL_LOW>;
		};

		dsi_ufoe@14019000 {
			compatible = "mediatek,dsi_ufoe";
			reg = <0x14019000 0x1000>;
			interrupts = <GIC_SPI 227 IRQ_TYPE_LEVEL_LOW>;
		};

		dsi_dsc@1401a000 {
			compatible = "mediatek,dsi_dsc";
			reg = <0x1401a000 0x1000>;
			interrupts = <GIC_SPI 228 IRQ_TYPE_LEVEL_LOW>;
		};

		dsi_split@1401b000 {
			compatible = "mediatek,dsi_split";
			reg = <0x1401b000 0x1000>;
		};

		dsi0@1401c000 {
			compatible = "mediatek,dsi0";
			reg = <0x1401c000 0x1000>;
			interrupts = <GIC_SPI 229 IRQ_TYPE_LEVEL_LOW>;
		};

		dsi1@1401d000 {
			compatible = "mediatek,dsi1";
			reg = <0x1401d000 0x1000>;
			interrupts = <GIC_SPI 230 IRQ_TYPE_LEVEL_LOW>;
		};

		dpi0@1401e000 {
			compatible = "mediatek,dpi0";
			reg = <0x1401e000 0x1000>;
			interrupts = <GIC_SPI 231 IRQ_TYPE_LEVEL_LOW>;
		};

		mm_mutex@1401f000 {
			compatible = "mediatek,mm_mutex";
			reg = <0x1401f000 0x1000>;
			interrupts = <GIC_SPI 202 IRQ_TYPE_LEVEL_LOW>;
		};

		smi_larb0@14020000 {
			compatible = "mediatek,smi_larb0";
			reg = <0x14020000 0x1000>;
			interrupts = <GIC_SPI 233 IRQ_TYPE_LEVEL_LOW>;
		};

		smi_larb5@14021000 {
			compatible = "mediatek,smi_larb5";
			reg = <0x14021000 0x1000>;
			interrupts = <GIC_SPI 234 IRQ_TYPE_LEVEL_LOW>;
		};

		smi_common@14022000 {
			compatible = "mediatek,smi_common";
			reg = <0x14022000 0x1000>;
		};

		imgsys_config@15000000  {
			compatible = "mediatek,imgsys_config";
			reg = <0x15000000  0x1000>;
		};

		smi_larb6@15001000 {
			compatible = "mediatek,smi_larb6";
			reg = <0x15001000 0x1000>;
			interrupts = <GIC_SPI 245 IRQ_TYPE_LEVEL_LOW>;
		};


		/* this device node is added manually for dip use */
		dip_a@15022000 {
			compatible = "mediatek,dip_a";
			reg = <0x15022000 0x4500>;
			interrupts = <GIC_SPI 260 IRQ_TYPE_LEVEL_LOW>;
		};

		dip_a0@15022000 {
			compatible = "mediatek,dip_a0";
			reg = <0x15022000 0x1000>;
			interrupts = <GIC_SPI 260 IRQ_TYPE_LEVEL_LOW>;
		};

		dip_a1@15023000 {
			compatible = "mediatek,dip_a1";
			reg = <0x15023000 0x1000>;
		};

		dip_a_nbc@15026000 {
			compatible = "mediatek,dip_a_nbc";
			reg = <0x15026000 0x1000>;
		};

		dpe@15028000 {
			compatible = "mediatek,dpe";
			reg = <0x15028000 0x1000>;
			interrupts = <GIC_SPI 261 IRQ_TYPE_LEVEL_LOW>;
		};

		fd@1502b000 {
			compatible = "mediatek,fd";
			reg = <0x1502b000 0x1000>;
			interrupts = <GIC_SPI 259 IRQ_TYPE_LEVEL_LOW>;
		};

		camsys_config@1a000000  {
			compatible = "mediatek,camsys_config";
			reg = <0x1a000000  0x1000>;
		};

		smi_larb2@1a001000 {
			compatible = "mediatek,smi_larb2";
			reg = <0x1a001000 0x1000>;
			interrupts = <GIC_SPI 258 IRQ_TYPE_LEVEL_LOW>;
		};

		camtop@1a003000 {
			compatible = "mediatek,camtop";
			reg = <0x1a003000 0x1000>;
			interrupts = <GIC_SPI 247 IRQ_TYPE_LEVEL_LOW>;
		};

		cama@1a004000 {
			compatible = "mediatek,cama";
			reg = <0x1a004000 0x1000>;
			interrupts = <GIC_SPI 248 IRQ_TYPE_LEVEL_LOW>;
		};

		camb@1a005000 {
			compatible = "mediatek,camb";
			reg = <0x1a005000 0x1000>;
			interrupts = <GIC_SPI 249 IRQ_TYPE_LEVEL_LOW>;
		};

		camtop_set@1a00b000 {
			compatible = "mediatek,camtop_set";
			reg = <0x1a00b000 0x1000>;
		};

		cama_set@1a00c000 {
			compatible = "mediatek,cama_set";
			reg = <0x1a00c000 0x1000>;
		};

		camb_set@1a00d000 {
			compatible = "mediatek,camb_set";
			reg = <0x1a00d000 0x1000>;
		};

		camtop_inner@1a013000 {
			compatible = "mediatek,camtop_inner";
			reg = <0x1a013000 0x1000>;
		};

		cama_inner@1a014000 {
			compatible = "mediatek,cama_inner";
			reg = <0x1a014000 0x1000>;
		};

		camb_inner@1a015000 {
			compatible = "mediatek,camb_inner";
			reg = <0x1a015000 0x1000>;
		};

		camtop_clr@1a01b000 {
			compatible = "mediatek,camtop_clr";
			reg = <0x1a01b000 0x1000>;
		};

		cama_clr@1a01c000 {
			compatible = "mediatek,cama_clr";
			reg = <0x1a01c000 0x1000>;
		};

		camb_clr@1a01d000 {
			compatible = "mediatek,camb_clr";
			reg = <0x1a01d000 0x1000>;
		};

		seninf0@1a040000 {
			compatible = "mediatek,seninf0";
			reg = <0x1a040000 0x1000>;
		};

		seninf1@1a041000 {
			compatible = "mediatek,seninf1";
			reg = <0x1a041000 0x1000>;
		};

		seninf2@1a042000 {
			compatible = "mediatek,seninf2";
			reg = <0x1a042000 0x1000>;
		};

		seninf3@1a043000 {
			compatible = "mediatek,seninf3";
			reg = <0x1a043000 0x1000>;
		};

		seninf4@1a044000 {
			compatible = "mediatek,seninf4";
			reg = <0x1a044000 0x1000>;
		};

		seninf5@1a045000 {
			compatible = "mediatek,seninf5";
			reg = <0x1a045000 0x1000>;
		};

		seninf6@1a046000 {
			compatible = "mediatek,seninf6";
			reg = <0x1a046000 0x1000>;
		};

		seninf7@1a047000 {
			compatible = "mediatek,seninf7";
			reg = <0x1a047000 0x1000>;
		};

		camsv00@1a050000 {
			compatible = "mediatek,camsv00";
			reg = <0x1a050000 0x1000>;
			interrupts = <GIC_SPI 252 IRQ_TYPE_LEVEL_LOW>;
		/* fix me: flag should be set to 0x8 when polarity is correct */
		};

		camsv01@1a051000 {
			compatible = "mediatek,camsv01";
			reg = <0x1a051000 0x1000>;
			interrupts = <GIC_SPI 253 IRQ_TYPE_LEVEL_LOW>;
		/* fix me: flag should be set to 0x8 when polarity is correct */
		};

		camsv10@1a052000 {
			compatible = "mediatek,camsv10";
			reg = <0x1a052000 0x1000>;
			interrupts = <GIC_SPI 254 IRQ_TYPE_LEVEL_LOW>;
		};

		camsv11@1a053000 {
			compatible = "mediatek,camsv11";
			reg = <0x1a053000 0x1000>;
			interrupts = <GIC_SPI 255 IRQ_TYPE_LEVEL_LOW>;
		};

		camsv20@1a054000 {
			compatible = "mediatek,camsv20";
			reg = <0x1a054000 0x1000>;
			interrupts = <GIC_SPI 256 IRQ_TYPE_LEVEL_LOW>;
		};

		camsv21@1a055000 {
			compatible = "mediatek,camsv21";
			reg = <0x1a055000 0x1000>;
			interrupts = <GIC_SPI 257 IRQ_TYPE_LEVEL_LOW>;
		};

		vdec_gcon@16000000 {
			compatible = "mediatek,vdec_gcon";
			reg = <0x16000000 0x10000>;
		};

		smi_larb1@16010000 {
			compatible = "mediatek,smi_larb1";
			reg = <0x16010000 0x10000>;
			interrupts = <GIC_SPI 241 IRQ_TYPE_LEVEL_LOW>;
		};

		vdec@16020000 {
			compatible = "mediatek,vdec";
			reg = <0x16020000 0x10000>;
			interrupts = <GIC_SPI 240 IRQ_TYPE_LEVEL_LOW>;
		};

		vld@16021000 {
			compatible = "mediatek,vld";
			reg = <0x16021000 0x800>;
		};

		vld_top@16021800 {
			compatible = "mediatek,vld_top";
			reg = <0x16021800 0x800>;
		};

		mc@16022000 {
			compatible = "mediatek,mc";
			reg = <0x16022000 0x1000>;
		};

		avc_vld@16023000 {
			compatible = "mediatek,avc_vld";
			reg = <0x16023000 0x1000>;
		};

		avc_mv@16024000 {
			compatible = "mediatek,avc_mv";
			reg = <0x16024000 0x1000>;
		};

		vdec_pp@16025000 {
			compatible = "mediatek,vdec_pp";
			reg = <0x16025000 0x1000>;
		};

		vp8_vld@16026800 {
			compatible = "mediatek,vp8_vld";
			reg = <0x16026800 0x800>;
		};

		vld2@16027800 {
			compatible = "mediatek,vld2";
			reg = <0x16027800 0x800>;
		};

		hevc_vld@16028000 {
			compatible = "mediatek,hevc_vld";
			reg = <0x16028000 0x1000>;
		};

		venc_gcon@17000000 {
			compatible = "mediatek,venc_gcon";
			reg = <0x17000000 0x1000>;
		};

		smi_larb3@17001000 {
			compatible = "mediatek,smi_larb3";
			reg = <0x17001000 0x1000>;
			interrupts = <GIC_SPI 236 IRQ_TYPE_LEVEL_LOW>;
		};

		venc@17002000 {
			compatible = "mediatek,venc";
			reg = <0x17002000 0x1000>;
			interrupts = <GIC_SPI 235 IRQ_TYPE_LEVEL_LOW>;
		};

		mjc_config@12000000 {
			compatible = "mediatek,mt6797-mjc_config";
			reg = <0x12000000 0x1000>;
			interrupts = <GIC_SPI 244 IRQ_TYPE_LEVEL_LOW>;
		};

		mjc_top@12001000 {
			compatible = "mediatek,mt6797-mjc_top";
			reg = <0x12001000 0x1000>;
			interrupts = <GIC_SPI 243 IRQ_TYPE_LEVEL_LOW>;
		};

		gps {
			compatible = "mediatek,mt3326-gps";
		};
	};
	mmc0_pins_default: mmc0@default {
			pins_cmd {
				drive-strength = /bits/ 8 <2>;
			};
			pins_dat {
				drive-strength = /bits/ 8 <2>;
			};
			pins_clk {
				drive-strength = /bits/ 8 <2>;
			};
			pins_rst {
				drive-strength = /bits/ 8 <2>;
			};
			pins_ds {
				drive-strength = /bits/ 8 <2>;
			};
	};

	mmc0_register_setting_default: mmc0@register_default {
		dat0rddly      = /bits/ 8 <0>;
		dat1rddly      = /bits/ 8 <0>;
		dat2rddly      = /bits/ 8 <0>;
		dat3rddly      = /bits/ 8 <0>;
		dat4rddly      = /bits/ 8 <0>;
		dat5rddly      = /bits/ 8 <0>;
		dat6rddly      = /bits/ 8 <0>;
		dat7rddly      = /bits/ 8 <0>;
		datwrddly      = /bits/ 8 <0>;
		cmdrrddly      = /bits/ 8 <0>;
		cmdrddly       = /bits/ 8 <0>;
		cmd_edge = /bits/ 8 <MSDC_SMPL_FALLING>;
		rdata_edge = /bits/ 8 <MSDC_SMPL_FALLING>;
		wdata_edge = /bits/ 8 <MSDC_SMPL_FALLING>;

		ett-hs200-cells = <12>;
		ett-hs200-default = <OFFSET_MSDC_PATCH_BIT0		MSDC_PB0_INT_DAT_LATCH_CK_SEL 0x0
				OFFSET_MSDC_PATCH_BIT0			MSDC_PB0_CKGEN_MSDC_DLY_SEL   0x0
				OFFSET_MSDC_PATCH_BIT1			MSDC_PB1_CMD_RSP_TA_CNTR      0x1
				OFFSET_MSDC_IOCON			MSDC_IOCON_RSPL               0x0
				OFFSET_MSDC_PAD_TUNE0			MSDC_PAD_TUNE0_CMDRDLY        0x7
				OFFSET_MSDC_PAD_TUNE0			MSDC_PAD_TUNE0_CMDRRDLY       0xb
				OFFSET_MSDC_PATCH_BIT1			MSDC_PB1_WRDAT_CRCS_TA_CNTR   0x1
				OFFSET_MSDC_PAD_TUNE0			MSDC_PAD_TUNE0_DATWRDLY       0xb
				OFFSET_MSDC_IOCON			MSDC_IOCON_W_D0SPL            0x0
				OFFSET_MSDC_DAT_RDDLY0			MSDC_DAT_RDDLY0_D0            0x7
				OFFSET_MSDC_PAD_TUNE0			MSDC_PAD_TUNE0_DATRRDLY       0x9
				OFFSET_MSDC_IOCON			MSDC_IOCON_R_D_SMPL           0x0>;

		ett-hs400-cells = <8>;
		ett-hs400-default = <OFFSET_MSDC_PATCH_BIT0		MSDC_PB0_INT_DAT_LATCH_CK_SEL	0x0
				OFFSET_MSDC_PATCH_BIT0			MSDC_PB0_CKGEN_MSDC_DLY_SEL	0x0
				OFFSET_EMMC50_PAD_DS_TUNE		MSDC_EMMC50_PAD_DS_TUNE_DLY1	0x2
				OFFSET_EMMC50_PAD_DS_TUNE		MSDC_EMMC50_PAD_DS_TUNE_DLY3	0x10
				OFFSET_MSDC_PATCH_BIT1			MSDC_PB1_CMD_RSP_TA_CNTR	0x1
				OFFSET_MSDC_IOCON			MSDC_IOCON_RSPL			0x0
				OFFSET_MSDC_PAD_TUNE0			MSDC_PAD_TUNE0_CMDRDLY		0x6
				OFFSET_MSDC_PAD_TUNE0			MSDC_PAD_TUNE0_CMDRRDLY		0x6>;
	};

	mmc1_pins_default: mmc1@default {
			pins_cmd {
				drive-strength = /bits/ 8 <3>;
			};
			pins_dat {
				drive-strength = /bits/ 8 <3>;
			};
			pins_clk {
				drive-strength = /bits/ 8 <3>;
			};
	};

	mmc1_pins_sdr104: mmc1@sdr104 {
			pins_cmd {
				drive-strength = /bits/ 8 <2>;
			};
			pins_dat {
				drive-strength = /bits/ 8 <2>;
			};
			pins_clk {
				drive-strength = /bits/ 8 <3>;
			};
	};

	mmc1_pins_sdr50: mmc1@sdr50 {
			pins_cmd {
				drive-strength = /bits/ 8 <2>;
			};
			pins_dat {
				drive-strength = /bits/ 8 <2>;
			};
			pins_clk {
				drive-strength = /bits/ 8 <3>;
			};
	};

	mmc1_pins_ddr50: mmc1@ddr50 {
			pins_cmd {
				drive-strength = /bits/ 8 <2>;
			};
			pins_dat {
				drive-strength = /bits/ 8 <2>;
			};
			pins_clk {
				drive-strength = /bits/ 8 <3>;
			};
	};

	mmc1_register_setting_default: mmc1@register_default {
			dat0rddly      = /bits/ 8 <0>;
			dat1rddly      = /bits/ 8 <0>;
			dat2rddly      = /bits/ 8 <0>;
			dat3rddly      = /bits/ 8 <0>;
			datwrddly      = /bits/ 8 <0>;
			cmdrrddly      = /bits/ 8 <0>;
			cmdrddly       = /bits/ 8 <0>;
			cmd_edge = /bits/ 8 <MSDC_SMPL_FALLING>;
			rdata_edge = /bits/ 8 <MSDC_SMPL_FALLING>;
			wdata_edge = /bits/ 8 <MSDC_SMPL_FALLING>;
	};

};
